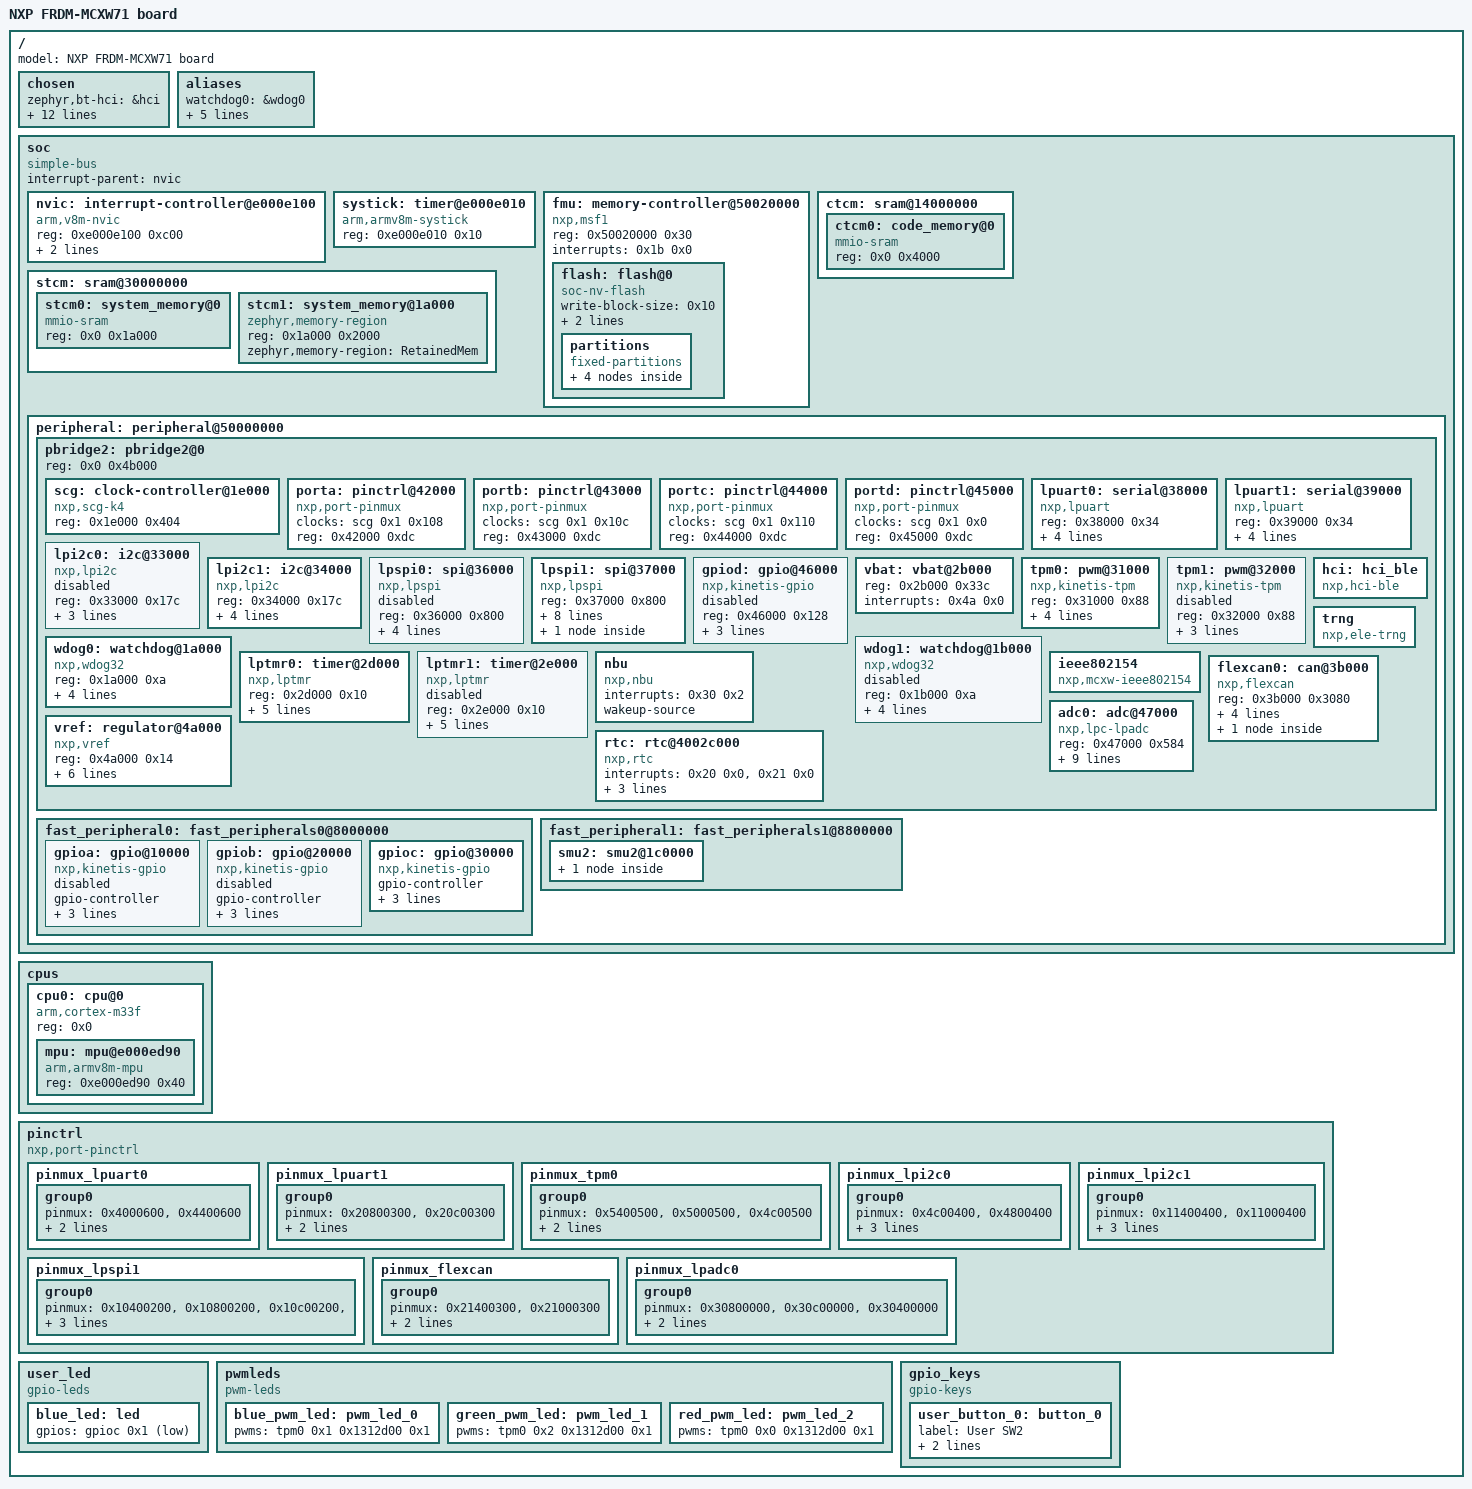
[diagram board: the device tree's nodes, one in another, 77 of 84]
/dts-v1/;

/ {
	#address-cells = < 0x1 >;
	#size-cells = < 0x1 >;
	model = "NXP FRDM-MCXW71 board";
	chosen {
		zephyr,bt-hci = &hci;
		zephyr,ieee802154 = &ieee802154;
		zephyr,entropy = &trng;
		zephyr,nbu = &nbu;
		zephyr,flash = &flash;
		zephyr,flash-controller = &fmu;
		zephyr,code-partition = &slot0_partition;
		zephyr,sram = &stcm0;
		zephyr,console = &lpuart1;
		zephyr,shell-uart = &lpuart1;
		zephyr,uart-pipe = &lpuart0;
		zephyr,canbus = &flexcan0;
		zephyr,uart-mcumgr = &lpuart0;
	};
	aliases {
		watchdog0 = &wdog0;
		led0 = &blue_led;
		sw0 = &user_button_0;
		blue-pwm-led = &blue_pwm_led;
		green-pwm-led = &green_pwm_led;
		red-pwm-led = &red_pwm_led;
	};
	soc {
		#address-cells = < 0x1 >;
		#size-cells = < 0x1 >;
		compatible = "simple-bus";
		interrupt-parent = < &nvic >;
		ranges;
		nvic: interrupt-controller@e000e100 {
			#address-cells = < 0x1 >;
			compatible = "arm,v8m-nvic";
			reg = < 0xe000e100 0xc00 >;
			interrupt-controller;
			#interrupt-cells = < 0x2 >;
			arm,num-irq-priority-bits = < 0x3 >;
			phandle = < 0x1 >;
		};
		systick: timer@e000e010 {
			compatible = "arm,armv8m-systick";
			reg = < 0xe000e010 0x10 >;
		};
		fmu: memory-controller@50020000 {
			#address-cells = < 0x1 >;
			#size-cells = < 0x1 >;
			compatible = "nxp,msf1";
			reg = < 0x50020000 0x30 >;
			interrupts = < 0x1b 0x0 >;
			status = "okay";
			ranges = < 0x0 0x10000000 0x100000 >;
			flash: flash@0 {
				compatible = "soc-nv-flash";
				write-block-size = < 0x10 >;
				erase-block-size = < 0x2000 >;
				reg = < 0x0 0x100000 >;
				partitions {
					compatible = "fixed-partitions";
					#address-cells = < 0x1 >;
					#size-cells = < 0x1 >;
					boot_partition: partition@0 {
						reg = < 0x0 0x10000 >;
					};
					slot0_partition: partition@10000 {
						reg = < 0x10000 0x6c000 >;
					};
					slot1_partition: partition@7C000 {
						reg = < 0x7c000 0x68000 >;
					};
					storage_partition: partition@E4000 {
						reg = < 0xe4000 0x1c000 >;
					};
				};
			};
		};
		ctcm: sram@14000000 {
			#address-cells = < 0x1 >;
			#size-cells = < 0x1 >;
			ranges = < 0x0 0x14000000 0x4000 >;
			ctcm0: code_memory@0 {
				compatible = "mmio-sram";
				reg = < 0x0 0x4000 >;
			};
		};
		stcm: sram@30000000 {
			#address-cells = < 0x1 >;
			#size-cells = < 0x1 >;
			ranges = < 0x0 0x30000000 0x1c000 >;
			stcm0: system_memory@0 {
				compatible = "mmio-sram";
				reg = < 0x0 0x1a000 >;
			};
			stcm1: system_memory@1a000 {
				compatible = "zephyr,memory-region", "mmio-sram";
				reg = < 0x1a000 0x2000 >;
				zephyr,memory-region = "RetainedMem";
			};
		};
		peripheral: peripheral@50000000 {
			ranges = < 0x0 0x50000000 0x10000000 >;
			#address-cells = < 0x1 >;
			#size-cells = < 0x1 >;
			pbridge2: pbridge2@0 {
				ranges;
				#address-cells = < 0x1 >;
				#size-cells = < 0x1 >;
				reg = < 0x0 0x4b000 >;
				scg: clock-controller@1e000 {
					compatible = "nxp,scg-k4";
					reg = < 0x1e000 0x404 >;
					#clock-cells = < 0x2 >;
					phandle = < 0x2 >;
				};
				porta: pinctrl@42000 {
					compatible = "nxp,port-pinmux";
					clocks = < &scg 0x1 0x108 >;
					reg = < 0x42000 0xdc >;
					phandle = < 0xd >;
				};
				portb: pinctrl@43000 {
					compatible = "nxp,port-pinmux";
					clocks = < &scg 0x1 0x10c >;
					reg = < 0x43000 0xdc >;
					phandle = < 0xe >;
				};
				portc: pinctrl@44000 {
					compatible = "nxp,port-pinmux";
					clocks = < &scg 0x1 0x110 >;
					reg = < 0x44000 0xdc >;
					phandle = < 0xf >;
				};
				portd: pinctrl@45000 {
					compatible = "nxp,port-pinmux";
					clocks = < &scg 0x1 0x0 >;
					reg = < 0x45000 0xdc >;
					phandle = < 0x8 >;
				};
				lpuart0: serial@38000 {
					compatible = "nxp,lpuart";
					reg = < 0x38000 0x34 >;
					interrupts = < 0x2c 0x0 >;
					clocks = < &scg 0x7 0xe0 >;
					status = "okay";
					current-speed = < 0x1c200 >;
					pinctrl-0 = < &pinmux_lpuart0 >;
					pinctrl-names = "default";
				};
				lpuart1: serial@39000 {
					compatible = "nxp,lpuart";
					reg = < 0x39000 0x34 >;
					interrupts = < 0x2d 0x0 >;
					clocks = < &scg 0x7 0xe4 >;
					status = "okay";
					current-speed = < 0x1c200 >;
					pinctrl-0 = < &pinmux_lpuart1 >;
					pinctrl-names = "default";
				};
				lpi2c0: i2c@33000 {
					compatible = "nxp,lpi2c";
					reg = < 0x33000 0x17c >;
					clock-frequency = < 0x186a0 >;
					#address-cells = < 0x1 >;
					#size-cells = < 0x0 >;
					interrupts = < 0x27 0x0 >;
					clocks = < &scg 0x7 0xe0 >;
					status = "disabled";
				};
				lpi2c1: i2c@34000 {
					compatible = "nxp,lpi2c";
					reg = < 0x34000 0x17c >;
					clock-frequency = < 0x186a0 >;
					#address-cells = < 0x1 >;
					#size-cells = < 0x0 >;
					interrupts = < 0x28 0x0 >;
					clocks = < &scg 0x7 0xe4 >;
					status = "okay";
					pinctrl-0 = < &pinmux_lpi2c1 >;
					pinctrl-names = "default";
				};
				lpspi0: spi@36000 {
					compatible = "nxp,lpspi";
					reg = < 0x36000 0x800 >;
					interrupts = < 0x2a 0x0 >;
					clocks = < &scg 0x7 0xd8 >;
					tx-fifo-size = < 0x8 >;
					rx-fifo-size = < 0x8 >;
					#address-cells = < 0x1 >;
					#size-cells = < 0x0 >;
					status = "disabled";
				};
				lpspi1: spi@37000 {
					compatible = "nxp,lpspi";
					reg = < 0x37000 0x800 >;
					interrupts = < 0x2b 0x0 >;
					clocks = < &scg 0x7 0xdc >;
					tx-fifo-size = < 0x8 >;
					rx-fifo-size = < 0x8 >;
					#address-cells = < 0x1 >;
					#size-cells = < 0x0 >;
					status = "okay";
					pinctrl-0 = < &pinmux_lpspi1 >;
					pinctrl-names = "default";
					pcs-sck-delay = < 0x5 >;
					sck-pcs-delay = < 0x5 >;
					transfer-delay = < 0x7d >;
					mx25r6435fm2il0: flash@0 {
						compatible = "jedec,spi-nor";
						jedec-id = [ C2 28 17 ];
						reg = < 0x0 >;
						wp-gpios = < &gpioc 0x0 0x1 >;
						size = < 0x4000000 >;
						has-dpd;
						dpd-wakeup-sequence = < 0x7530 0x14 0x88b8 >;
						t-enter-dpd = < 0x2710 >;
						mxicy,mx25r-power-mode = "low-power";
						spi-max-frequency = < 0x7a1200 >;
					};
				};
				gpiod: gpio@46000 {
					compatible = "nxp,kinetis-gpio";
					reg = < 0x46000 0x128 >;
					interrupts = < 0x41 0x0 >, < 0x42 0x0 >;
					gpio-controller;
					#gpio-cells = < 0x2 >;
					nxp,kinetis-port = < &portd >;
					status = "disabled";
				};
				vbat: vbat@2b000 {
					reg = < 0x2b000 0x33c >;
					interrupts = < 0x4a 0x0 >;
				};
				tpm0: pwm@31000 {
					compatible = "nxp,kinetis-tpm";
					reg = < 0x31000 0x88 >;
					interrupts = < 0x25 0x0 >;
					clocks = < &scg 0x7 0xc4 >;
					prescaler = < 0x10 >;
					status = "okay";
					#pwm-cells = < 0x3 >;
					pinctrl-0 = < &pinmux_tpm0 >;
					pinctrl-names = "default";
					phandle = < 0x10 >;
				};
				tpm1: pwm@32000 {
					compatible = "nxp,kinetis-tpm";
					reg = < 0x32000 0x88 >;
					interrupts = < 0x26 0x0 >;
					clocks = < &scg 0x7 0xc8 >;
					prescaler = < 0x10 >;
					status = "disabled";
					#pwm-cells = < 0x3 >;
				};
				wdog0: watchdog@1a000 {
					compatible = "nxp,wdog32";
					reg = < 0x1a000 0xa >;
					interrupts = < 0x17 0x0 >;
					clocks = < &scg 0x5 0x68 >;
					clk-source = < 0x1 >;
					clk-divider = < 0x100 >;
					status = "okay";
				};
				wdog1: watchdog@1b000 {
					compatible = "nxp,wdog32";
					reg = < 0x1b000 0xa >;
					interrupts = < 0x18 0x0 >;
					clocks = < &scg 0x5 0x6c >;
					clk-source = < 0x1 >;
					clk-divider = < 0x100 >;
					status = "disabled";
				};
				lptmr0: timer@2d000 {
					compatible = "nxp,lptmr";
					reg = < 0x2d000 0x10 >;
					interrupts = < 0x22 0x0 >;
					clock-frequency = < 0x7d00 >;
					clk-source = < 0x2 >;
					prescaler = < 0x1 >;
					resolution = < 0x20 >;
					status = "okay";
				};
				lptmr1: timer@2e000 {
					compatible = "nxp,lptmr";
					reg = < 0x2e000 0x10 >;
					interrupts = < 0x23 0x0 >;
					clock-frequency = < 0x7d00 >;
					clk-source = < 0x2 >;
					prescaler = < 0x1 >;
					resolution = < 0x20 >;
					status = "disabled";
				};
				nbu: nbu {
					compatible = "nxp,nbu";
					interrupts = < 0x30 0x2 >;
					interrupt-names = "nbu_rx_int";
					status = "okay";
					wakeup-source;
				};
				hci: hci_ble {
					compatible = "nxp,hci-ble";
				};
				ieee802154: ieee802154 {
					compatible = "nxp,mcxw-ieee802154";
				};
				trng: trng {
					compatible = "nxp,ele-trng";
				};
				flexcan0: can@3b000 {
					compatible = "nxp,flexcan";
					reg = < 0x3b000 0x3080 >;
					interrupts = < 0x2f 0x0 >;
					interrupt-names = "common";
					clocks = < &scg 0x7 0xec >;
					clk-source = < 0x2 >;
					status = "okay";
					pinctrl-0 = < &pinmux_flexcan >;
					pinctrl-names = "default";
					can-transceiver {
						max-bitrate = < 0x4c4b40 >;
					};
				};
				adc0: adc@47000 {
					compatible = "nxp,lpc-lpadc";
					reg = < 0x47000 0x584 >;
					interrupts = < 0x47 0x0 >;
					clocks = < &scg 0x7 0x11c >;
					voltage-ref = < 0x1 >;
					calibration-average = < 0x80 >;
					power-level = < 0x0 >;
					offset-value-a = < 0x0 >;
					offset-value-b = < 0x0 >;
					#io-channel-cells = < 0x1 >;
					nxp,references = < &vref 0x708 >;
					status = "okay";
					pinctrl-0 = < &pinmux_lpadc0 >;
					pinctrl-names = "default";
				};
				vref: regulator@4a000 {
					compatible = "nxp,vref";
					reg = < 0x4a000 0x14 >;
					regulator-name = "mcxw71-vref";
					#nxp,reference-cells = < 0x1 >;
					nxp,buffer-startup-delay-us = < 0x190 >;
					nxp,bandgap-startup-time-us = < 0x14 >;
					regulator-min-microvolt = < 0xf4240 >;
					regulator-max-microvolt = < 0x200b20 >;
					nxp,current-compensation-en;
					status = "okay";
					phandle = < 0xb >;
				};
				rtc: rtc@4002c000 {
					compatible = "nxp,rtc";
					status = "okay";
					interrupts = < 0x20 0x0 >, < 0x21 0x0 >;
					interrupt-names = "alarm", "seconds";
					clock-frequency = < 0x8000 >;
					prescaler = < 0x8000 >;
					reg = < 0x4002c000 0x50 >;
				};
			};
			fast_peripheral0: fast_peripherals0@8000000 {
				#address-cells = < 0x1 >;
				#size-cells = < 0x1 >;
				ranges = < 0x0 0x8000000 0x40000 >;
				gpioa: gpio@10000 {
					compatible = "nxp,kinetis-gpio";
					status = "disabled";
					gpio-controller;
					#gpio-cells = < 0x2 >;
					nxp,kinetis-port = < &porta >;
					reg = < 0x10000 0x128 >;
					interrupts = < 0x3b 0x0 >, < 0x3c 0x0 >;
				};
				gpiob: gpio@20000 {
					compatible = "nxp,kinetis-gpio";
					status = "disabled";
					gpio-controller;
					#gpio-cells = < 0x2 >;
					nxp,kinetis-port = < &portb >;
					reg = < 0x20000 0x128 >;
					interrupts = < 0x3d 0x0 >, < 0x3e 0x0 >;
				};
				gpioc: gpio@30000 {
					compatible = "nxp,kinetis-gpio";
					status = "okay";
					gpio-controller;
					#gpio-cells = < 0x2 >;
					nxp,kinetis-port = < &portc >;
					reg = < 0x30000 0x128 >;
					interrupts = < 0x3f 0x0 >, < 0x40 0x0 >;
					phandle = < 0x7 >;
				};
			};
			fast_peripheral1: fast_peripherals1@8800000 {
				#address-cells = < 0x1 >;
				#size-cells = < 0x1 >;
				ranges = < 0x0 0x8800000 0x20a000 >;
				smu2: smu2@1c0000 {
					#address-cells = < 0x1 >;
					#size-cells = < 0x1 >;
					ranges = < 0x0 0x1c0000 0xa000 >;
					rpmsgmem: memory@8800 {
						compatible = "zephyr,memory-region", "mmio-sram";
						reg = < 0x8800 0x1800 >;
						zephyr,memory-region = "rpmsg_sh_mem";
						zephyr,memory-attr = < 0x100000 >;
					};
				};
			};
		};
	};
	cpus {
		#address-cells = < 0x1 >;
		#size-cells = < 0x0 >;
		cpu0: cpu@0 {
			compatible = "arm,cortex-m33f";
			reg = < 0x0 >;
			#address-cells = < 0x1 >;
			#size-cells = < 0x1 >;
			mpu: mpu@e000ed90 {
				compatible = "arm,armv8m-mpu";
				reg = < 0xe000ed90 0x40 >;
			};
		};
	};
	pinctrl: pinctrl {
		compatible = "nxp,port-pinctrl";
		pinmux_lpuart0: pinmux_lpuart0 {
			phandle = < 0x3 >;
			group0 {
				pinmux = < 0x4000600 >, < 0x4400600 >;
				drive-strength = "low";
				slew-rate = "fast";
			};
		};
		pinmux_lpuart1: pinmux_lpuart1 {
			phandle = < 0x4 >;
			group0 {
				pinmux = < 0x20800300 >, < 0x20c00300 >;
				drive-strength = "low";
				slew-rate = "fast";
			};
		};
		pinmux_tpm0: pinmux_tpm0 {
			phandle = < 0x9 >;
			group0 {
				pinmux = < 0x5400500 >, < 0x5000500 >, < 0x4c00500 >;
				drive-strength = "low";
				slew-rate = "fast";
			};
		};
		pinmux_lpi2c0: pinmux_lpi2c0 {
			group0 {
				pinmux = < 0x4c00400 >, < 0x4800400 >;
				drive-strength = "low";
				slew-rate = "fast";
				drive-open-drain;
			};
		};
		pinmux_lpi2c1: pinmux_lpi2c1 {
			phandle = < 0x5 >;
			group0 {
				pinmux = < 0x11400400 >, < 0x11000400 >;
				drive-strength = "low";
				slew-rate = "fast";
				drive-open-drain;
			};
		};
		pinmux_lpspi1: pinmux_lpspi1 {
			phandle = < 0x6 >;
			group0 {
				pinmux = < 0x10400200 >, < 0x10800200 >, < 0x10c00200 >, < 0x10000200 >;
				slew-rate = "fast";
				drive-strength = "low";
			};
		};
		pinmux_flexcan: pinmux_flexcan {
			phandle = < 0xa >;
			group0 {
				pinmux = < 0x21400300 >, < 0x21000300 >;
				slew-rate = "slow";
				drive-strength = "low";
			};
		};
		pinmux_lpadc0: pinmux_lpadc0 {
			phandle = < 0xc >;
			group0 {
				pinmux = < 0x30800000 >, < 0x30c00000 >, < 0x30400000 >;
				drive-strength = "low";
				slew-rate = "fast";
			};
		};
	};
	user_led {
		compatible = "gpio-leds";
		blue_led: led {
			gpios = < &gpioc 0x1 0x1 >;
		};
	};
	pwmleds {
		compatible = "pwm-leds";
		blue_pwm_led: pwm_led_0 {
			pwms = < &tpm0 0x1 0x1312d00 0x1 >;
		};
		green_pwm_led: pwm_led_1 {
			pwms = < &tpm0 0x2 0x1312d00 0x1 >;
		};
		red_pwm_led: pwm_led_2 {
			pwms = < &tpm0 0x0 0x1312d00 0x1 >;
		};
	};
	gpio_keys {
		compatible = "gpio-keys";
		user_button_0: button_0 {
			label = "User SW2";
			gpios = < &gpioc 0x6 0x1 >;
			zephyr,code = < 0xb >;
			status = "okay";
		};
	};
};
